AUTOSAR XML (schema 4-3-0)
standard types defined: UINT8, UINT16, UINT32, UINT64, SINT8, SINT16, SINT32, SINT64, FLOAT32, FLOAT64
package /Cluster
  can cluster PT_CAN: baudrate=500000, protocol-name=CAN, can-fd-baudrate=2000000
    can physical channel PT_CAN_Channel: comm-connectors=[ECM_PT_CAN, TCU_PT_CAN, BCM_PT_CAN, ABS_PT_CAN]
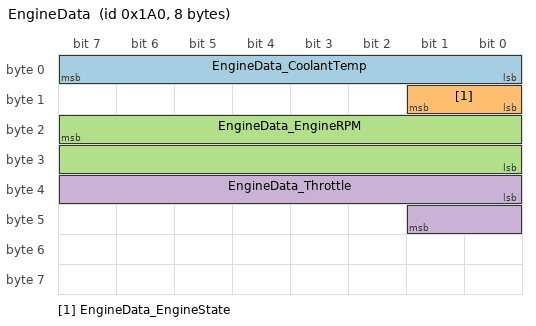
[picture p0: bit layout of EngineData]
      frame EngineData: id 0x1A0, from ECM, to BCM ABS TCU, frame-length=8, can-addressing-mode=STANDARD, can-frame-rx-behavior=CAN-20, can-frame-tx-behavior=CAN-20  # Engine speed and temperatures
        pdu EngineData: length=8, transmission-mode-true-timing=cyclic-timing=time-period=0.01, unused-bit-pattern=0
          signal EngineData_CoolantTemp: start 0, 8 bit, little-endian, init-value=130, base-type=UINT8, compu {phys=raw-40 for raw 0..255}, unit=°C, transfer-property=PENDING
          signal EngineData_EngineState: start 8, 2 bit, little-endian, init-value=2, base-type=UINT8, compu {0=Off, 1=Cranking, 2=Running, 3=Error, phys=raw for raw 0..3}, transfer-property=PENDING
          signal EngineData_EngineRPM: start 23, 16 bit, big-endian, init-value=12000, base-type=UINT16, compu {phys=raw*0.25 for raw 0..65535}, unit=rpm, transfer-property=PENDING
          signal EngineData_Throttle: start 32, 10 bit, little-endian, init-value=235, base-type=UINT16, compu {phys=raw*0.1 for raw 0..1023}, unit=%, transfer-property=PENDING
      frame VehicleSpeed: id 0xB4, from ABS, to BCM ECM, frame-length=4, can-addressing-mode=STANDARD, can-frame-rx-behavior=CAN-20, can-frame-tx-behavior=CAN-20
        pdu VehicleSpeed: length=4, transmission-mode-true-timing=cyclic-timing=time-period=0.02, unused-bit-pattern=0
          signal VehicleSpeed_VehSpeed: start 7, 13 bit, big-endian, init-value=1200, base-type=UINT16, compu {phys=raw*0.05 for raw 0..8191}, unit=km/h, transfer-property=PENDING
          signal VehicleSpeed_SpeedValid: start 16, 1 bit, little-endian, init-value=1, base-type=UINT8, compu {identical}, transfer-property=PENDING
      frame GearInfo: id 0x1F0, from TCU, to ECM BCM, frame-length=2, can-addressing-mode=STANDARD, can-frame-rx-behavior=CAN-20, can-frame-tx-behavior=CAN-20
        pdu GearInfo: length=2, transmission-mode-true-timing=cyclic-timing=time-period=0.05, unused-bit-pattern=0
          signal GearInfo_Gear: start 0, 4 bit, little-endian, init-value=4, base-type=UINT8, compu {phys=raw-1 for raw 0..15}, transfer-property=PENDING
      frame BodyStatus: id 0x3C0, from BCM, to ECM, frame-length=8, can-addressing-mode=STANDARD, can-frame-rx-behavior=CAN-20, can-frame-tx-behavior=CAN-20
        pdu BodyStatus: length=8, transmission-mode-true-timing=cyclic-timing=time-period=0.1, unused-bit-pattern=0
          signal BodyStatus_DoorOpen: start 0, 4 bit, little-endian, init-value=0, base-type=UINT8, compu {identical}, transfer-property=PENDING
          signal BodyStatus_AmbientTemp: start 8, 12 bit, little-endian, init-value=315, base-type=SINT16, compu {phys=raw*0.1 for raw -2048..2047}, unit=°C, transfer-property=PENDING
      frame BatteryFD: id 0x18FF5010, from ECM, to BCM, frame-length=24, can-addressing-mode=EXTENDED, can-frame-rx-behavior=CAN-FD, can-frame-tx-behavior=CAN-FD  # CAN FD 20-byte battery frame
        pdu BatteryFD: length=24, transmission-mode-true-timing=cyclic-timing=time-period=0.1, unused-bit-pattern=0
          signal BatteryFD_PackVoltage: start 0, 16 bit, little-endian, init-value=39840, base-type=UINT16, compu {phys=raw*0.01 for raw 0..65535}, unit=V, transfer-property=PENDING
          signal BatteryFD_PackCurrent: start 16, 16 bit, little-endian, init-value=-125, base-type=SINT16, compu {phys=raw*0.1 for raw -32768..32767}, unit=A, transfer-property=PENDING
          signal BatteryFD_CellTempMax: start 32, 8 bit, little-endian, init-value=75, base-type=UINT8, compu {phys=raw-40 for raw 0..255}, unit=°C, transfer-property=PENDING
          signal BatteryFD_SOC: start 63, 10 bit, big-endian, init-value=764, base-type=UINT16, compu {phys=raw*0.1 for raw 0..1023}, unit=%, transfer-property=PENDING
package /ECU
  4 x ecu instance:
    ECM  # Engine control module
      can communication connector ECM_PT_CAN
    TCU  # Transmission control unit
      can communication connector TCU_PT_CAN
    BCM  # Body control module (our node)
      can communication connector BCM_PT_CAN
    ABS  # Brake controller
      can communication connector ABS_PT_CAN
package /Unit
  6 x unit:
    U__C: display-name=°C
    U_rpm: display-name=rpm
    U__: display-name=%
    U_km_h: display-name=km/h
    U_V: display-name=V
    U_A: display-name=A
